# nRF7140_graphics register map
Vendor: Nordic Semiconductor; Series: nRF71; File version: 1
CPU: CM33 r0p4, little endian, MPU, FPU, 3 interrupt priority bits, 480 interrupts
Registers are 32-bit, read-write, reset 0x0 unless marked. A register's access mark holds for its fields unless they carry their own. Offsets are from the block's base; [hi:lo] are bit positions; lines under a group give offsets from that group; 'fields as' and 'values as' point back to an identical list.

## GLOBAL_PDM130_NS — Pulse Density Modulation (Digital Microphone) Interface 0
Base 0x4F9A7000
Same registers: GLOBAL_PDM131_NS 0x4F9B7000, GLOBAL_PDM132_NS 0x4F9C7000, GLOBAL_PDM133_NS 0x4F9D7000, GLOBAL_PDM130_S 0x5F9A7000, GLOBAL_PDM131_S 0x5F9B7000, GLOBAL_PDM132_S 0x5F9C7000, GLOBAL_PDM133_S 0x5F9D7000
0x00 TASKS_DMA group — Peripheral tasks.
  0x00 START wo — Starts operation using easyDMA to load the values. See peripheral description for operation using easyDMA.
    [0] START
      1=Trigger task
  0x04 STOP wo — Stops operation using easyDMA. This does not trigger an END event. After a STOP task, the easyDMA (channel) will also enter its lowest required power level.
    [0] STOP
      1=Trigger task
0x80 SUBSCRIBE_DMA group — Subscribe configuration for tasks
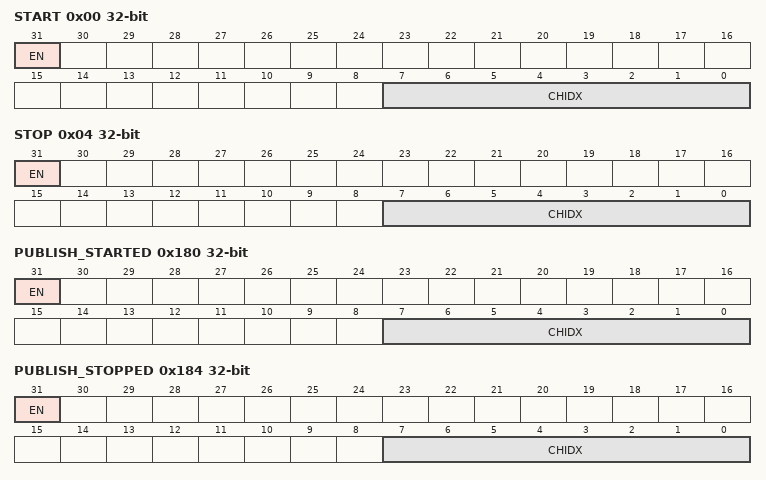
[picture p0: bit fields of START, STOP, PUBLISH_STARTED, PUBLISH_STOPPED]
  0x00 START — Subscribe configuration for task START
    [31] EN
      0=Disabled (Disable subscription); 1=Enabled (Enable subscription)
    [7:0] CHIDX — DPPI channel that task START will subscribe to
  0x04 STOP — Subscribe configuration for task STOP
    [31] EN
      values as SUBSCRIBE_DMA.START.EN
    [7:0] CHIDX — DPPI channel that task STOP will subscribe to
0x100 EVENTS_STARTED — PDM transfer has started
  [0] EVENTS_STARTED
    0=NotGenerated (Event not generated); 1=Generated (Event generated)
0x104 EVENTS_STOPPED — PDM transfer has finished
  [0] EVENTS_STOPPED
    values as EVENTS_STARTED.EVENTS_STARTED
0x110 EVENTS_DMA group — Peripheral events.
  0x00 END — Generated after all MAXCNT bytes have been transferred Equivalent to eventDmaEnd[Channel]
    [0] END
      values as EVENTS_STARTED.EVENTS_STARTED
  0x04 READY — Generated when EasyDMA has buffered the .PTR and .MAXCNT registers for the channel, allowing them to be written to prepare for the next sequence.
    [0] READY
      values as EVENTS_STARTED.EVENTS_STARTED
  0x08 BUSERROR — An error occured during the bus transfer. This event is generated on an AHB / AXI error response.
    [0] BUSERROR
      values as EVENTS_STARTED.EVENTS_STARTED
0x180 PUBLISH_STARTED — Publish configuration for event STARTED
  [31] EN
    0=Disabled (Disable publishing); 1=Enabled (Enable publishing)
  [7:0] CHIDX — DPPI channel that event STARTED will publish to
0x184 PUBLISH_STOPPED — Publish configuration for event STOPPED
  [31] EN
    values as PUBLISH_STARTED.EN
  [7:0] CHIDX — DPPI channel that event STOPPED will publish to
0x190 PUBLISH_DMA group — Publish configuration for events
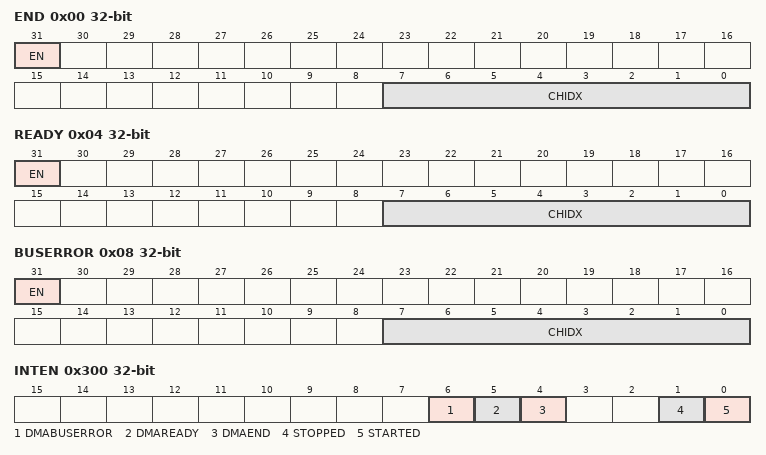
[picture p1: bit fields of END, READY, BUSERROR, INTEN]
  0x00 END — Publish configuration for event END
    [31] EN
      values as PUBLISH_STARTED.EN
    [7:0] CHIDX — DPPI channel that event END will publish to
  0x04 READY — Publish configuration for event READY
    [31] EN
      values as PUBLISH_STARTED.EN
    [7:0] CHIDX — DPPI channel that event READY will publish to
  0x08 BUSERROR — Publish configuration for event BUSERROR
    [31] EN
      values as PUBLISH_STARTED.EN
    [7:0] CHIDX — DPPI channel that event BUSERROR will publish to
0x200 SHORTS — Shortcuts between local events and tasks
  [0] DMA_BUSERROR_STOP — Shortcut between event DMA.BUSERROR and task STOP
    0=Disabled (Disable shortcut); 1=Enabled (Enable shortcut)
0x300 INTEN — Enable or disable interrupt
  [all] fields
    0=Disabled; 1=Enabled
  [6] DMABUSERROR — Enable or disable interrupt for event DMABUSERROR
  [5] DMAREADY — Enable or disable interrupt for event DMAREADY
  [4] DMAEND — Enable or disable interrupt for event DMAEND
  [1] STOPPED — Enable or disable interrupt for event STOPPED
  [0] STARTED — Enable or disable interrupt for event STARTED
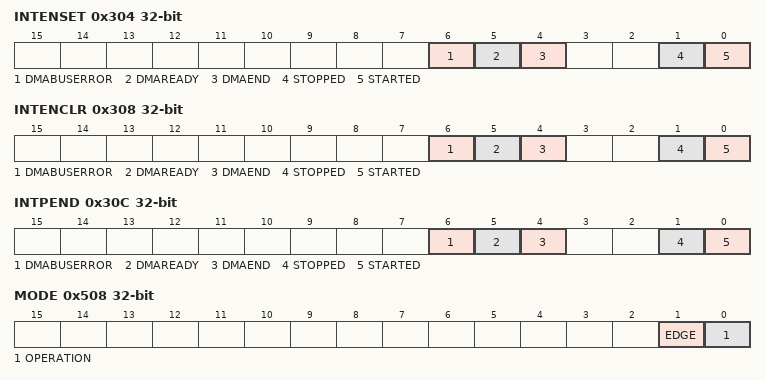
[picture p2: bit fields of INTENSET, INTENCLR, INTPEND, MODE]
0x304 INTENSET — Enable interrupt
  [all] fields
    on read: 0=Disabled (Read: Disabled); 1=Enabled (Read: Enabled) | on write: 1=Set (Enable)
  [6] DMABUSERROR — Write '1' to enable interrupt for event DMABUSERROR
  [5] DMAREADY — Write '1' to enable interrupt for event DMAREADY
  [4] DMAEND — Write '1' to enable interrupt for event DMAEND
  [1] STOPPED — Write '1' to enable interrupt for event STOPPED
  [0] STARTED — Write '1' to enable interrupt for event STARTED
0x308 INTENCLR — Disable interrupt
  [all] fields
    on read: 0=Disabled (Read: Disabled); 1=Enabled (Read: Enabled) | on write: 1=Clear (Disable)
  [6] DMABUSERROR — Write '1' to disable interrupt for event DMABUSERROR
  [5] DMAREADY — Write '1' to disable interrupt for event DMAREADY
  [4] DMAEND — Write '1' to disable interrupt for event DMAEND
  [1] STOPPED — Write '1' to disable interrupt for event STOPPED
  [0] STARTED — Write '1' to disable interrupt for event STARTED
0x30C INTPEND ro — Pending interrupts
  [all] fields
    on read: 0=NotPending (Read: Not pending); 1=Pending (Read: Pending)
  [6] DMABUSERROR — Read pending status of interrupt for event DMABUSERROR
  [5] DMAREADY — Read pending status of interrupt for event DMAREADY
  [4] DMAEND — Read pending status of interrupt for event DMAEND
  [1] STOPPED — Read pending status of interrupt for event STOPPED
  [0] STARTED — Read pending status of interrupt for event STARTED
0x500 ENABLE — PDM module enable register
  [0] ENABLE — Enable or disable PDM module
    0=Disabled; 1=Enabled
0x504 PDMCLKCTRL reset 0x8400000 — PDM clock generator control
  [31:0] FREQ — PDM_CLK frequency configuration. Enumerations are deprecated, use PDMCLKCTRL equation to find the register value. The 12 least significant bits of the register are ignored and shall be set to zero.
    0x8000000=1000K (PDM_CLK = 32 MHz / 32 = 1.000 MHz); 0x8400000=Default (PDM_CLK = 32 MHz / 31 = 1.032 MHz. Nominal clock for RATIO=Ratio64. Assumes a 20 bit Baud Rate Generator (BRG) dividing the 32 MHz clock. Output of BRG is connected to PDM_CLK, the filter source clock requires twice that rate, a frequency doubler is built in the module to provide 2.048 MHz, which implies a filter clockdiv ratio hardcoded at x2 to the IP.); 0x8800000=1067K (PDM_CLK = 32 MHz / 30 = 1.067 MHz); 0x9800000=1231K (PDM_CLK = 32 MHz / 26 = 1.231 MHz); 0xA000000=1280K (PDM_CLK = 32 MHz / 25 = 1.280 MHz. Nominal clock for RATIO=Ratio80.); 0xA800000=1333K (PDM_CLK = 32 MHz / 24 = 1.333 MHz)
0x508 MODE — Defines the routing of the connected PDM microphones' signals
  [1] EDGE — Defines on which PDM_CLK edge left (or mono) is sampled
    0=LeftFalling (Left (or mono) is sampled on falling edge of PDM_CLK); 1=LeftRising (Left (or mono) is sampled on rising edge of PDM_CLK)
  [0] OPERATION — Mono or stereo operation Mono also disables the gated clock to the right filter bank
    0=Stereo (Sample and store one pair (left + right) of 16-bit samples per RAM word R=[31:16]; L=[15:0]); 1=Mono (Sample and store two successive left samples (16 bits each) per RAM word L1=[31:16]; L0=[15:0])
0x50C FDBYPASS — Bypass the frequency doubler in the PDM clock generation
  [0] BYPASS — Bypass the frequency doubler in the PDM clock generation, and revert to a simple divider structure.
    0=DoublerActive (PDMCLKCTRL determines directly the PDM_CLK frequency. A doubler is used to provide twice that clock to the filters. This allows better accuracy on PDM_CLK.); 1=DividerActive (PDMCLKCTRL determines the clock provided to the filters, PDM_CLK is generated by dividing that clock by two. This results in less accuracy on PDM_CLK.)
0x510 RXDLDATA ro — Left sample from filter output
  [15:0] RXDLDATA
0x514 RXDRDATA ro — Right sample from filter output
  [15:0] RXDRDATA
0x518 GAINL reset 0x28 — Left output gain adjustment
  [6:0] GAINL — Left output gain adjustment, in 0.5 dB steps, around the default module gain (see electrical parameters) 0x00 -20 dB gain adjust 0x01 -19.5 dB gain adjust (...) 0x27 -0.5 dB gain adjust 0x28 0 dB gain adjust 0x29 +0.5 dB gain adjust (...) 0x4F +19.5 dB gain adjust 0x50 +20 dB gain adjust 0x51 +20 dB gain adjust 0x52 +20 dB gain adjust (...)
    0=MinGain (-20 dB gain adjustment (minimum)); 40=DefaultGain (0 dB gain adjustment); 80=MaxGain (+20 dB gain adjustment (maximum))
0x51C GAINR reset 0x28 — Right output gain adjustment
  [6:0] GAINR — Right output gain adjustment, in 0.5 dB steps, around the default module gain (see electrical parameters)
    values as GAINL.GAINL
0x520 RATIO — Selects the ratio between PDM_CLK and output sample rate. Change PDMCLKCTRL accordingly.
  [0] RATIO — Selects the ratio between PDM_CLK and output sample rate
    0=Ratio of 64; 1=Ratio of 80
0x528 FILTER group — Unspecified
  0x00 HPPOLE reset 0xC — Settings for the high-pass filter
    [3:0] HPPOLE — Settings for the high-pass filter -3dB gain pole, assuming filter source clock of 2.048 MHz
      15=p10 (10 Hz); 14=p20 (20 Hz); 13=p40 (40 Hz); 12=p80 (80 Hz); 11=p160 (159 Hz); 10=p320 (318 Hz); 9=p640 (636 Hz); 8=p1k2 (1271 Hz); 7=p2k5 (2537 Hz); 6=p5k (5054 Hz); 5=p10k (10031 Hz); 4=p19k (19767 Hz); 3=p38k (38436 Hz); 2=p73k (73037 Hz); 1=p134k (134010 Hz)
  0x04 HPDISABLE — High pass filter disable
    [0] DISABLE
      0=Enable (High pass filter enabled); 1=Disable (High pass filter disabled)
  0x08 SOFTMUTE — Soft mute function
    [0] ENABLE
      0=Disabled (Disable soft mute function); 1=Enabled (Enable soft mute function)
  0x0C SOFTCYCLES — Soft mute settings
    [2:0] DISABLE — Soft mute settings: amount of cycles for transition
      0=s16 (16 filter source clock cycles); 1=s32 (32 filter source clock cycles); 2=s48 (48 filter source clock cycles); 3=s64 (64 filter source clock cycles); 4=s80 (80 filter source clock cycles); 5=s96 (96 filter source clock cycles); 6=s112 (112 filter source clock cycles); 7=s128 (128 filter source clock cycles)
  0x10 SAMPLEDELAY — Input Data Sampling with Number of PDM_CLK Clock Cycle Delay
    [0] DELAY
      0=x2 (2x cycles); 1=x4 (4x cycles)
0x53C PHASE — Selection of delay on the clock line (to avoid potential setup&hold timing violation on input data)
  [3:0] PHASE — To avoid potential setup&hold timing violation on input data, this register provides selection between 14 phase delay registers (15 taps), which each provide an additional 31.25ns delay of pdmClockToPad relative to pdmClockToFilter.
0x540 PSEL group — Unspecified
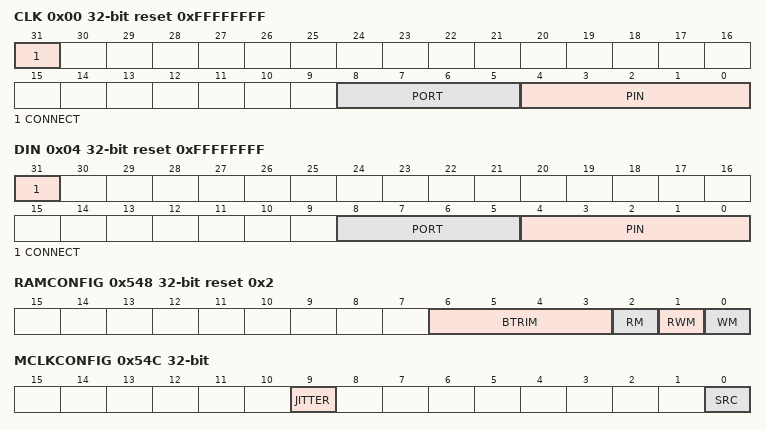
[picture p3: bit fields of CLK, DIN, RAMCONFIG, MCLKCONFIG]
  0x00 CLK reset 0xFFFFFFFF — Pin number configuration for PDM CLK signal
    [31] CONNECT — Connection
      1=Disconnected; 0=Connected
    [8:5] PORT — Port number
    [4:0] PIN — Pin number
  0x04 DIN reset 0xFFFFFFFF — Pin number configuration for PDM DIN signal
    fields as PSEL.CLK
0x548 RAMCONFIG reset 0x2 — Trim value for internal PDM RAM
  [6:3] BTRIM — Source Bias Trim Adjustment
  [2] RM — Read Margin Adjustment
  [1] RWM — Read/Write Margin Adjustment
  [0] WM — Write Margin Adjustment
0x54C MCLKCONFIG — Master clock generator configuration
  [9] JITTER — Enable jittering master clock.
    0=Disable jitter; 1=Enable jitter
  [0] SRC — Master clock source selection
    0=PCLK32M (32 MHz peripheral clock); 1=ACLK (Audio PLL clock)
0x700 DMA group — Unspecified
  0x00 ENABLE — Register doesn't do anything. Can be written and read, but has no functionality attached.
    [0] ENABLE
      0=Disabled; 1=Enabled
  0x04 PTR — RAM buffer start address
    [31:0] PTR — RAM buffer start address for this EasyDMA channel. This address is a word aligned Data RAM address.
  0x08 MAXCNT — Maximum number of bytes in receive buffer
    [15:0] MAXCNT
  0x0C AMOUNT ro — Number of bytes transferred in the last transaction, updated after the END event.
    [15:0] AMOUNT — Number of bytes transferred in the last transaction. In case of NACK error, includes the NACK'ed byte.
  0x1C TERMINATEONBUSERROR — Terminate the transaction if a BUSERROR event is detected.
    [0] ENABLE
      0=Disabled; 1=Enabled
  0x20 BUSERRORADDRESS — Address of transaction that generated the last BUSERROR event.
    [31:0] ADDRESS
